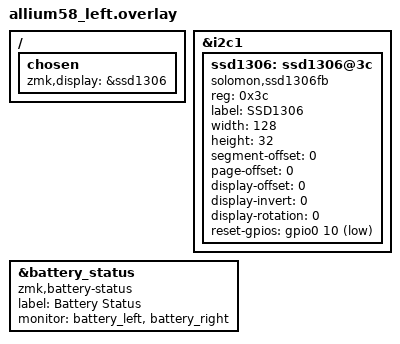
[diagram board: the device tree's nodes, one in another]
/ {
    chosen {
        zmk,display = &ssd1306;
    };
};

&i2c1 {
    status = "okay";

    ssd1306: ssd1306@3c {
        compatible = "solomon,ssd1306fb";
        reg = <0x3c>;
        label = "SSD1306";
        width = <128>;
        height = <32>;
        segment-offset = <0>;
        page-offset = <0>;
        display-offset = <0>;
        display-invert = <0>;
        display-rotation = <0>;
        reset-gpios = <&gpio0 10 GPIO_ACTIVE_LOW>;
        status = "okay";
    };
};

&battery_status {
    compatible = "zmk,battery-status";
    label = "Battery Status";
    monitor = <&battery_left>, <&battery_right>;
};
